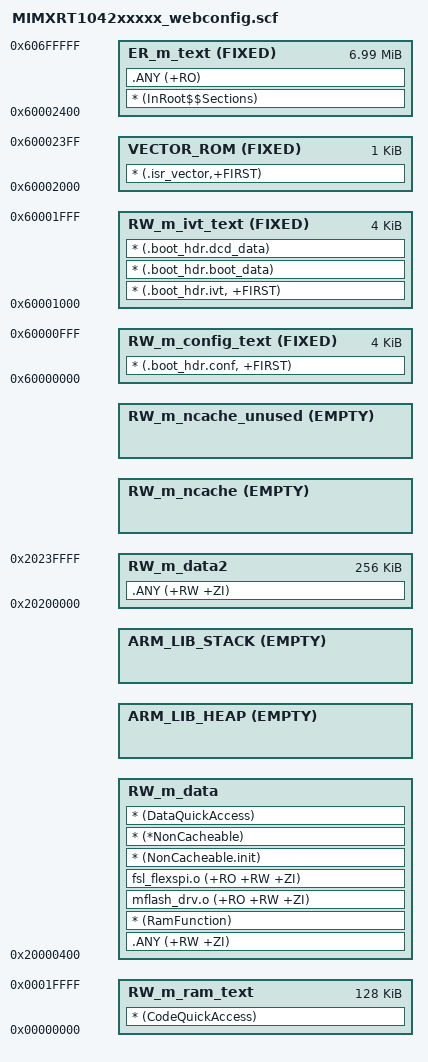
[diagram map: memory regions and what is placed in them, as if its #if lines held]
#!armclang --target=arm-arm-none-eabi -mcpu=cortex-m7 -E -x c
/*
** ###################################################################
**     Processors:          MIMXRT1042DFP6B
**                          MIMXRT1042XFP5B
**                          MIMXRT1042XJM5B
**
**     Compiler:            Keil ARM C/C++ Compiler
**     Reference manual:    IMXRT1040RM Rev.A, 09/2021
**     Version:             rev. 0.1, 2021-07-20
**     Build:               b220420
**
**     Abstract:
**         Linker file for the Keil ARM C/C++ Compiler
**
**     Copyright 2016 Freescale Semiconductor, Inc.
**     Copyright 2016-2022 NXP
**     All rights reserved.
**
**     SPDX-License-Identifier: BSD-3-Clause
**
**     http:                 www.nxp.com
**     mail:                 support@nxp.com
**
** ###################################################################
*/

#if (defined(__ram_vector_table__))
  #define __ram_vector_table_size__    0x00000400
#else
  #define __ram_vector_table_size__    0x00000000
#endif

#define m_flash_config_start           0x60000000
#define m_flash_config_size            0x00001000

#define m_ivt_start                    0x60001000
#define m_ivt_size                     0x00001000

#define m_interrupts_start             0x60002000
#define m_interrupts_size              0x00000400

#define m_text_start                   0x60002400
#define m_text_size                    0x006FDC00

/* Reserved area for "mflash_files" */
#define  m_mflash_start                0x60700000
#define  m_mflash_size                 0x00100000

#define m_qacode_start                 0x00000000
#define m_qacode_size                  0x00020000

#define m_interrupts_ram_start         0x20000000
#define m_interrupts_ram_size          __ram_vector_table_size__

#define m_data_start                   (m_interrupts_ram_start + m_interrupts_ram_size)
#define m_data_size                    (0x00020000 - m_interrupts_ram_size)

#define m_data2_start                  0x20200000
#define m_data2_size                   0x00040000

/* Sizes */
#if (defined(__stack_size__))
  #define Stack_Size                   __stack_size__
#else
  #define Stack_Size                   0x0400
#endif

#if (defined(__heap_size__))
  #define Heap_Size                    __heap_size__
#else
  #define Heap_Size                    0x0400
#endif


LR_m_text m_flash_config_start m_text_start+m_text_size-m_flash_config_start {   ; load region size_region
  RW_m_config_text m_flash_config_start FIXED m_flash_config_size { ; load address = execution address
    * (.boot_hdr.conf, +FIRST)
  }

  RW_m_ivt_text m_ivt_start FIXED m_ivt_size { ; load address = execution address
    * (.boot_hdr.ivt, +FIRST)
    * (.boot_hdr.boot_data)
    * (.boot_hdr.dcd_data)
  }

  VECTOR_ROM m_interrupts_start FIXED m_interrupts_size { ; load address = execution address
    * (.isr_vector,+FIRST)
  }
  ER_m_text m_text_start FIXED m_text_size { ; load address = execution address
    * (InRoot$$Sections)
    .ANY (+RO)
  }
  RW_m_data m_data_start m_data_size-Stack_Size-Heap_Size { ; RW data
    .ANY (+RW +ZI)
    * (RamFunction)
    /* Necessary to run flash routines from SRAM */
    mflash_drv.o (+RO +RW +ZI)
    fsl_flexspi.o (+RO +RW +ZI)
    * (NonCacheable.init)
    * (*NonCacheable)
    * (DataQuickAccess)
  }
  ARM_LIB_HEAP +0 EMPTY Heap_Size {    ; Heap region growing up
  }
  ARM_LIB_STACK m_data_start+m_data_size EMPTY -Stack_Size { ; Stack region growing down
  }
  RW_m_ram_text m_qacode_start m_qacode_size { ;
    * (CodeQuickAccess)
  }
  RW_m_data2 m_data2_start m_data2_size { ; RW data2
    .ANY (+RW +ZI)
  }
  RW_m_ncache +0 EMPTY 0 {
  }
  RW_m_ncache_unused +0 EMPTY m_data2_size-ImageLength(RW_m_data2)-ImageLength(RW_m_ncache) { ; Empty region added for MPU configuration
  }
}
